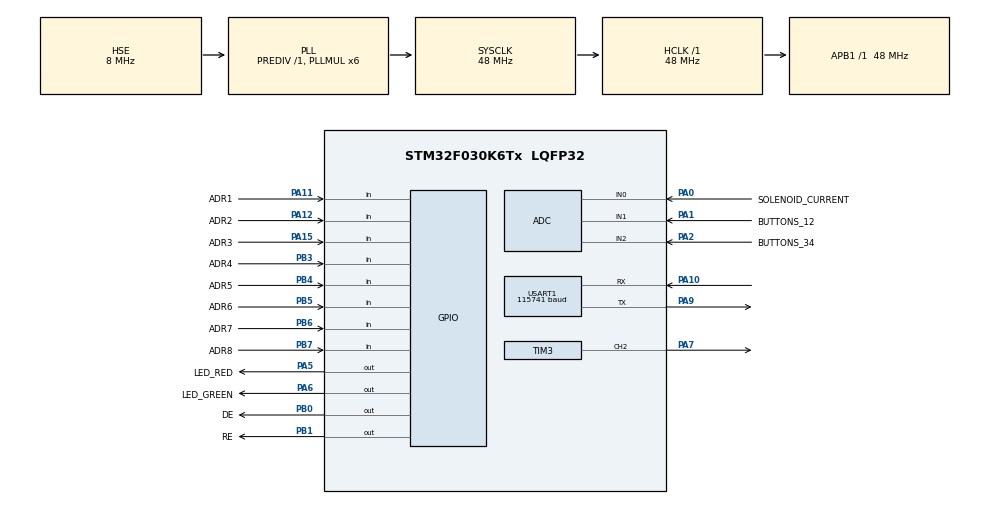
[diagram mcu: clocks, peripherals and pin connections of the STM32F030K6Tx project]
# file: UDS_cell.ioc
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Mcu.Family=STM32F0
Mcu.Name=STM32F030K6Tx
Mcu.Package=LQFP32
PA0.GPIO_Label=SOLENOID_CURRENT
PA0.Mode=IN0
PA0.Signal=ADC_IN0
PA1.GPIO_Label=BUTTONS_12
PA1.Mode=IN1
PA1.Signal=ADC_IN1
PA10.Mode=Asynchronous
PA10.Signal=USART1_RX
PA11.GPIO_Label=ADR1
PA11.Signal=GPIO_Input
PA12.GPIO_Label=ADR2
PA12.Signal=GPIO_Input
PA13.Mode=Serial_Wire
PA13.Signal=SYS_SWDIO
PA14.Mode=Serial_Wire
PA14.Signal=SYS_SWCLK
PA15.GPIO_Label=ADR3
PA15.Signal=GPIO_Input
PA2.GPIO_Label=BUTTONS_34
PA2.Mode=IN2
PA2.Signal=ADC_IN2
PA5.GPIO_Label=LED_RED
PA5.Signal=GPIO_Output
PA6.GPIO_Label=LED_GREEN
PA6.Signal=GPIO_Output
PA7.Signal=S_TIM3_CH2
PA9.Mode=Asynchronous
PA9.Signal=USART1_TX
PB0.GPIO_Label=DE
PB0.Signal=GPIO_Output
PB1.GPIO_Label=RE
PB1.Signal=GPIO_Output
PB3.GPIO_Label=ADR4
PB3.Signal=GPIO_Input
PB4.GPIO_Label=ADR5
PB4.Signal=GPIO_Input
PB5.GPIO_Label=ADR6
PB5.Signal=GPIO_Input
PB6.GPIO_Label=ADR7
PB6.Signal=GPIO_Input
PB7.GPIO_Label=ADR8
PB7.Signal=GPIO_Input
PF0-OSC_IN.Mode=HSE-External-Oscillator
PF0-OSC_IN.Signal=RCC_OSC_IN
PF1-OSC_OUT.Mode=HSE-External-Oscillator
PF1-OSC_OUT.Signal=RCC_OSC_OUT
ProjectManager.HeapSize=0x200
ProjectManager.StackSize=0x400
ProjectManager.TargetToolchain=MDK-ARM V5
RCC.AHBFreq_Value=48000000
RCC.APB1Freq_Value=48000000
RCC.APB1TimFreq_Value=48000000
RCC.HCLKFreq_Value=48000000
RCC.HSIState=RCC_HSI_ON
RCC.PLLMUL=RCC_PLL_MUL6
RCC.PLLSourceVirtual=RCC_PLLSOURCE_HSE
RCC.SYSCLKFreq_VALUE=48000000
RCC.SYSCLKSource=RCC_SYSCLKSOURCE_PLLCLK
SH.S_TIM3_CH2.0=TIM3_CH2,PWM Generation2 CH2
TIM3.Channel-PWM\ Generation2\ CH2=TIM_CHANNEL_2
TIM3.Period=65535
TIM3.Prescaler=10000
USART1.BaudRate=115741
board=UDS_cell

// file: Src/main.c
/**
  ******************************************************************************
  * File Name          : main.c
  * Description        : Main program body
  ******************************************************************************
  *
  * COPYRIGHT(c) 2017 STMicroelectronics
  *
  * Redistribution and use in source and binary forms, with or without modification,
  * are permitted provided that the following conditions are met:
  *   1. Redistributions of source code must retain the above copyright notice,
  *      this list of conditions and the following disclaimer.
  *   2. Redistributions in binary form must reproduce the above copyright notice,
  *      this list of conditions and the following disclaimer in the documentation
  *      and/or other materials provided with the distribution.
  *   3. Neither the name of STMicroelectronics nor the names of its contributors
  *      may be used to endorse or promote products derived from this software
  *      without specific prior written permission.
  *
  * THIS SOFTWARE IS PROVIDED BY THE COPYRIGHT HOLDERS AND CONTRIBUTORS "AS IS"
  * AND ANY EXPRESS OR IMPLIED WARRANTIES, INCLUDING, BUT NOT LIMITED TO, THE
  * IMPLIED WARRANTIES OF MERCHANTABILITY AND FITNESS FOR A PARTICULAR PURPOSE ARE
  * DISCLAIMED. IN NO EVENT SHALL THE COPYRIGHT HOLDER OR CONTRIBUTORS BE LIABLE
  * FOR ANY DIRECT, INDIRECT, INCIDENTAL, SPECIAL, EXEMPLARY, OR CONSEQUENTIAL
  * DAMAGES (INCLUDING, BUT NOT LIMITED TO, PROCUREMENT OF SUBSTITUTE GOODS OR
  * SERVICES; LOSS OF USE, DATA, OR PROFITS; OR BUSINESS INTERRUPTION) HOWEVER
  * CAUSED AND ON ANY THEORY OF LIABILITY, WHETHER IN CONTRACT, STRICT LIABILITY,
  * OR TORT (INCLUDING NEGLIGENCE OR OTHERWISE) ARISING IN ANY WAY OUT OF THE USE
  * OF THIS SOFTWARE, EVEN IF ADVISED OF THE POSSIBILITY OF SUCH DAMAGE.
  *
  ******************************************************************************
  */
#include "stm32f0xx_hal.h"
#include "adc.h"
#include "tim.h"
#include "usart.h"
#include "gpio.h"

/* USER CODE BEGIN Includes */
#include "global.h"
#include "timer.h"
#include "pins.h"
//20170309 - add adr #14
//20201001 - remove checking disconnecting state solenoid

/* USER CODE END Includes */

/* USER CODE BEGIN PV */
/* Private variables ---------------------------------------------------------*/

/* USER CODE END PV */

void SystemClock_Config(void);
void Error_Handler(void);

/* USER CODE BEGIN PFP */
/* Private function prototypes -----------------------------------------------*/

/* USER CODE END PFP */

int main(void)
{

  /* MCU Configuration----------------------------------------------------------*/

  /* Reset of all peripherals, Initializes the Flash interface and the Systick. */
  HAL_Init();

  /* Configure the system clock */
  SystemClock_Config();

  /* Initialize all configured peripherals */
  MX_GPIO_Init();
  MX_USART1_UART_Init();
  MX_TIM3_Init();
  MX_ADC_Init();

  /* USER CODE BEGIN 2 */
	UART1_EnableRI();
	RS485_RX;
	init_timer17(1);

	//UART1_SendString("Start\r\n");
  /* USER CODE END 2 */

  /* Infinite loop */
  while (1)
  {

  /* USER CODE BEGIN 3 */

	/*
		sprintf(buf,"%04d\r\n",tmp);
		UART1_SendString(buf);
		HAL_Delay(500);*/
  }

  /* USER CODE END 3 */

}

/** System Clock Configuration
*/
void SystemClock_Config(void)
{

  RCC_OscInitTypeDef RCC_OscInitStruct;
  RCC_ClkInitTypeDef RCC_ClkInitStruct;
  RCC_PeriphCLKInitTypeDef PeriphClkInit;

  RCC_OscInitStruct.OscillatorType = RCC_OSCILLATORTYPE_HSI14|RCC_OSCILLATORTYPE_HSE;
  RCC_OscInitStruct.HSEState = RCC_HSE_ON;
  RCC_OscInitStruct.HSI14State = RCC_HSI14_ON;
  RCC_OscInitStruct.HSI14CalibrationValue = 16;
  RCC_OscInitStruct.PLL.PLLState = RCC_PLL_ON;
  RCC_OscInitStruct.PLL.PLLSource = RCC_PLLSOURCE_HSE;
  RCC_OscInitStruct.PLL.PLLMUL = RCC_PLL_MUL6;
  RCC_OscInitStruct.PLL.PREDIV = RCC_PREDIV_DIV1;
  if (HAL_RCC_OscConfig(&RCC_OscInitStruct) != HAL_OK)
  {
    Error_Handler();
  }

  RCC_ClkInitStruct.ClockType = RCC_CLOCKTYPE_HCLK|RCC_CLOCKTYPE_SYSCLK
                              |RCC_CLOCKTYPE_PCLK1;
  RCC_ClkInitStruct.SYSCLKSource = RCC_SYSCLKSOURCE_PLLCLK;
  RCC_ClkInitStruct.AHBCLKDivider = RCC_SYSCLK_DIV1;
  RCC_ClkInitStruct.APB1CLKDivider = RCC_HCLK_DIV1;
  if (HAL_RCC_ClockConfig(&RCC_ClkInitStruct, FLASH_LATENCY_1) != HAL_OK)
  {
    Error_Handler();
  }

  PeriphClkInit.PeriphClockSelection = RCC_PERIPHCLK_USART1;
  PeriphClkInit.Usart1ClockSelection = RCC_USART1CLKSOURCE_PCLK1;
  if (HAL_RCCEx_PeriphCLKConfig(&PeriphClkInit) != HAL_OK)
  {
    Error_Handler();
  }

  HAL_SYSTICK_Config(HAL_RCC_GetHCLKFreq()/1000);

  HAL_SYSTICK_CLKSourceConfig(SYSTICK_CLKSOURCE_HCLK);

  /* SysTick_IRQn interrupt configuration */
  HAL_NVIC_SetPriority(SysTick_IRQn, 0, 0);
}

void Error_Handler(void)
{
  while(1)
  {
  }
}

/************************ (C) COPYRIGHT STMicroelectronics *****END OF FILE****/
